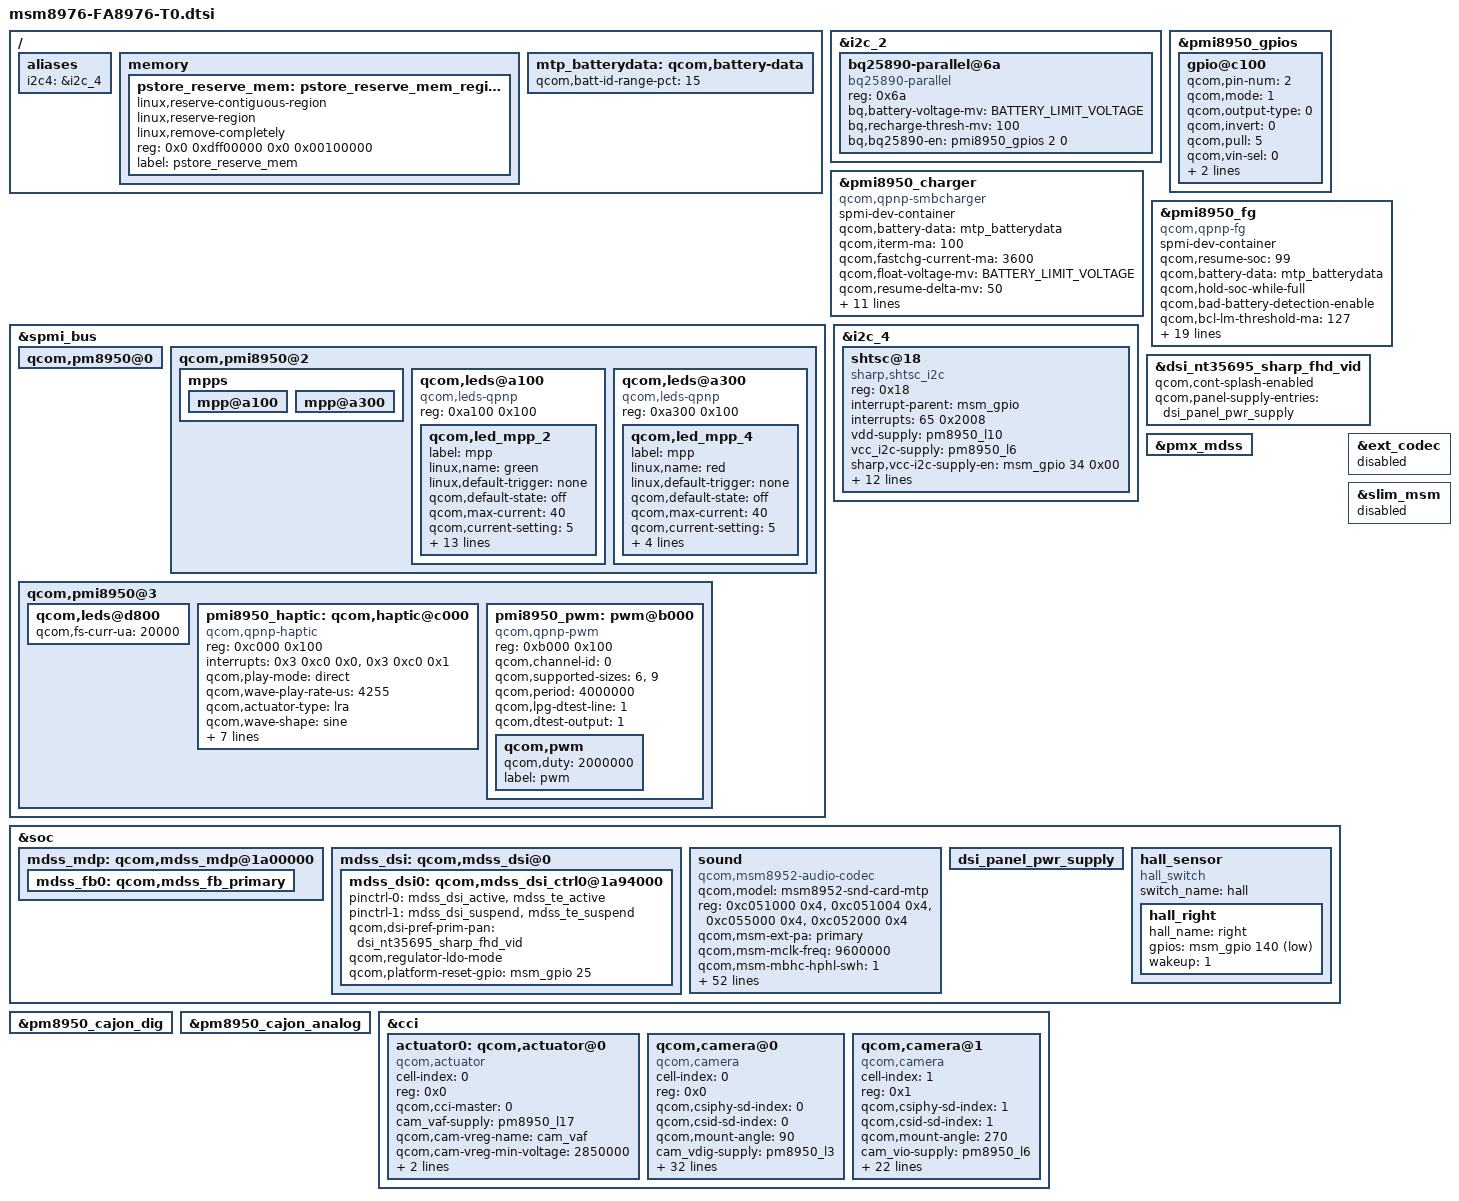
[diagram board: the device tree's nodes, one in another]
/* Copyright (c) 2014, The Linux Foundation. All rights reserved.
 *
 * This program is free software; you can redistribute it and/or modify
 * it under the terms of the GNU General Public License version 2 and
 * only version 2 as published by the Free Software Foundation.
 *
 * This program is distributed in the hope that it will be useful,
 * but WITHOUT ANY WARRANTY; without even the implied warranty of
 * MERCHANTABILITY or FITNESS FOR A PARTICULAR PURPOSE.  See the
 * GNU General Public License for more details.
 */

/* project CPA8_931 */
#define BATTERY_LIMIT_VOLTAGE           (4400)
#define BATTERY_CV_THRESHOLD (BATTERY_LIMIT_VOLTAGE-10)
/ {
       aliases {
                i2c4 = &i2c_4;
        };
	memory {
    		pstore_reserve_mem: pstore_reserve_mem_region@0 {
            	linux,reserve-contiguous-region;
                linux,reserve-region;
                linux,remove-completely;
                reg = <0x0 0xdff00000 0x0 0x00100000>;//3GB DDR, will override at driver code for a right value, so dont take care this value. frankie. 2016-03-15.
                label = "pstore_reserve_mem";
        };
	};
};

/* Begin add bq25890 en configuration */
&i2c_2 { /* BLSP1 QUP2 */
             bq25890-parallel@6a {
                     compatible = "bq25890-parallel";
                     reg = <0x6a>;
                     bq,battery-voltage-mv = <BATTERY_LIMIT_VOLTAGE>;
                     bq,recharge-thresh-mv = <100>;
                     bq,bq25890-en = <&pmi8950_gpios 2 0>;
                  };
};
&pmi8950_gpios {
                gpio@c100 {
                     qcom,pin-num = <2>;
                     qcom,mode = <1>;
                     qcom,output-type = <0>;
                     qcom,invert = <0>;
                     qcom,pull = <5>;
                     qcom,vin-sel = <0>;
                     qcom,src-sel = <2>;
                     qcom,master-en = <1>;
                     status = "okay";
               };
};
/* End add bq25890 en configuration */
/* add pmi zkxiong */
 &pmi8950_charger{
           spmi-dev-container;
           compatible = "qcom,qpnp-smbcharger";
           #address-cells = <1>;
           #size-cells = <1>;
  
	   qcom,battery-data = <&mtp_batterydata>;
           qcom,iterm-ma = <100>;
           qcom,fastchg-current-ma = <3600>;//100mA more
           qcom,float-voltage-mv = <BATTERY_LIMIT_VOLTAGE>;
           qcom,resume-delta-mv = <50>;
   //      /delete-property/ qcom,chg-inhibit-fg;
	   /delete-property/ qcom,chg-led-support;
           /delete-property/ qcom,chg-led-sw-controls;
           qcom,chg-inhibit-fg;
           qcom,dc-psy-type = "Mains";
           qcom,dc-psy-ma = <1500>;
           qcom,rparasitic-uohm = <100000>;
           qcom,bms-psy-name = "bms";
           qcom,thermal-mitigation = <2100 1800 1500 1200 900 600 0>;
           qcom,parallel-usb-min-current-ma = <1500>;
           qcom,parallel-usb-9v-min-current-ma = <1000>;
           qcom,parallel-allowed-lowering-ma = <600>;
           qcom,autoadjust-vfloat;
           /delete-property/ qcom,charge-unknown-battery;
   };

 &pmi8950_fg{
          spmi-dev-container;
          compatible = "qcom,qpnp-fg";
          #address-cells = <1>;
          #size-cells = <1>;
          qcom,resume-soc = <99>;
	  qcom,battery-data = <&mtp_batterydata>;
	  qcom,hold-soc-while-full;
	  qcom,bad-battery-detection-enable;
          status = "okay";
          qcom,bcl-lm-threshold-ma = <127>;
          qcom,bcl-mh-threshold-ma = <405>;
          qcom,fg-cutoff-voltage-mv = <3350>;
          qcom,fg-iterm-ma = <500>;
          qcom,fg-chg-iterm-ma = <100>;
	  qcom,cycle-counter-low-soc = <15>;
 	  qcom,cycle-counter-high-soc = <85>;
          qcom,ext-sense-type;
          qcom,cycle-counter-en;
          qcom,cycle-counter-low-soc = <15>;
          qcom,cycle-counter-high-soc = <85>;
          qcom,capacity-learning-on;
          qcom,fg-cc-cv-threshold-mv = <BATTERY_CV_THRESHOLD>;
          qcom,ext-sense-type;
	  qcom,thermal-coefficients = <0xC2 0x86 0xBB 0x50 0xCF 0x37>;
	  qcom,cold-bat-decidegc = <0>;
          qcom,hot-bat-decidegc = <500>;
          qcom,cool-bat-decidegc = <100>;
          qcom,warm-bat-decidegc = <440>;
          qcom,fg-vbatt-low-threshold = <3600>;
	  qcom,fg-delta-soc = <2>;
  };
/{
mtp_batterydata: qcom,battery-data {
			 qcom,batt-id-range-pct = <15>;
#include "batterydata_CPAT366_100K.dtsi"
#include "batterydata_CPLD373_10K.dtsi"
#include "batterydata_CPTM366_1M.dtsi"
		 };
};
/* end pmi add */

&spmi_bus {
         qcom,pm8950@0 {
                /delete-node/ qcom,leds@a300;
        };
        /*add for led by fengdongjie*/
         qcom,pmi8950@2 {
                mpps{
                      mpp@a100 {status = "okay";};
                      mpp@a300 {status = "okay";};
                };
                /delete-node/ qcom,leds@a100;
                qcom,leds@a100 {
                        compatible = "qcom,leds-qpnp";
                        reg = <0xa100 0x100>;
                        status = "okay";
                        qcom,led_mpp_2 {
                        label = "mpp";
                        linux,name = "green";
                        linux,default-trigger = "none";
                        qcom,default-state = "off";
                        qcom,max-current = <40>;
                        qcom,current-setting = <5>;
                        qcom,use-blink;
                        qcom,id = <6>;
                        qcom,mode = "pwm";
                        qcom,source-sel = <8>;
                        qcom,mode-ctrl = <0x60>;
                        qcom,pwm-channel = <0>;
                        qcom,pwm-us = <2000000>;
                        qcom,start-idx = <1>;
                        qcom,ramp-step-ms = <120>;
                        qcom,duty-pcts = [00 00 00 00 00
                                00 00 00 00 00
                                50 00 00 00 00
                                00 00 00 00 00
                                00];
                        pwms = <&pmi8950_pwm 0 0>;
                        pwm-names="green";
             };
        };
             qcom,leds@a300 {
                  compatible = "qcom,leds-qpnp";
                  reg = <0xa300 0x100>;
                  status = "okay";
                  qcom,led_mpp_4 {
                          label = "mpp";
                          linux,name = "red";
                          linux,default-trigger = "none";
                          qcom,default-state = "off";
                          qcom,max-current = <40>;
                          qcom,current-setting = <5>;
                          qcom,id = <6>;
                          qcom,mode = "manual";
                          qcom,source-sel = <1>;
                          qcom,mode-ctrl = <0x60>;
                  };
           };
   };
         qcom,pmi8950@3 {
                qcom,leds@d800 {
                         qcom,fs-curr-ua = <20000>;
                        /delete-property/ qcom,en-ext-pfet-sc-pro;
                        };
                pmi8950_haptic: qcom,haptic@c000 {
                        compatible = "qcom,qpnp-haptic";
                        reg = <0xc000 0x100>;
                        interrupts = <0x3 0xc0 0x0>,
                                   <0x3 0xc0 0x1>;
                        interrupt-names = "sc-irq", "play-irq";
                        qcom,play-mode = "direct";
                        qcom,wave-play-rate-us = <4255>;
                        qcom,actuator-type = "lra";
                        qcom,wave-shape = "sine";
                        qcom,vmax-mv = <1160>;
                        qcom,ilim-ma = <100>;
                        qcom,sc-deb-cycles = <8>;
                        //qcom,int-pwm-freq-khz = <505>;
                        //qcom,en-brake;
                        qcom,brake-pattern = [03 03 00 00];
                        //qcom,use-play-irq;
                        //qcom,use-sc-irq;
                        qcom,wave-samples = [3e 3e 3e 3e 3e 3e 3e 3e];
                        qcom,wave-rep-cnt = <1>;
                        qcom,wave-samp-rep-cnt = <1>;
                };
                /*add for led by fengdongjie*/
                /delete-node/  pwm@b000;
                pmi8950_pwm: pwm@b000 {
                     compatible = "qcom,qpnp-pwm";
                     reg = <0xb000 0x100>;
                     reg-names = "qpnp-lpg-channel-base";
                     qcom,channel-id = <0>;
                     qcom,supported-sizes = <6>, <9>;
                     qcom,period = <4000000>;
                     qcom,lpg-dtest-line = <1>;
                     qcom,dtest-output = <1>;
                     #pwm-cells = <2>;
                     qcom,pwm {
                             qcom,duty = <2000000>; //PWM duty time in microseconds
                             label = "pwm";
                     };
             };
      };
};

&i2c_4 {
         /* shtsc tw */
	shtsc@18 {
		compatible = "sharp,shtsc_i2c";	
		reg = <0x18>;
		interrupt-parent = <&msm_gpio>;
		interrupts = <65 0x2008>;// high-level trigger. but hard coded in the source.
		vdd-supply = <&pm8950_l10>;
		vcc_i2c-supply = <&pm8950_l6>;
		sharp,vcc-i2c-supply-en = <&msm_gpio 34 0x00>;
		sharp,reset-gpio = <&msm_gpio 64 0x00>;
		sharp,irq-gpio = <&msm_gpio 65 0x2008>;
		pinctrl-names = "pmx_ts_active","pmx_ts_suspend";
		pinctrl-0 = <&ts_int_active &ts_reset_active>;
		pinctrl-1 = <&ts_int_suspend &ts_reset_suspend>;
		sharp,panel-coords = <0 0 1079 1919>; // depends on an LCD resolution (0 0 Xmax-1 Ymax-1)
		sharp,display-coords = <0 0 1079 1919>; // depends on an LCD resolution (0 0 Xmax-1 Ymax-1)
		sharp,i2c-pull-up;
		ts_touch_num_max = <10>;
		ts_pressure_max = <65535>;
		ts_flip_x = <0>;
		ts_flip_y = <0>;
		ts_swap_xy = <0>;

	};
};


/* start william add dtsi for related lcd*/
/* qcom original file: msm8952-mtp.dtsi */
#include "yulong-dsi-panel-nt35695-sharp-fhd-550-video.dtsi"
&dsi_nt35695_sharp_fhd_vid {
        qcom,cont-splash-enabled;
        qcom,panel-supply-entries = <&dsi_panel_pwr_supply>;
};
&pmx_mdss {
	/delete-property/ qcom,num-grp-pins;
	/delete-property/ qcom,pins;
};

&mdss_dsi0 {
	pinctrl-names = "mdss_default", "mdss_sleep";
	pinctrl-0 = <&mdss_dsi_active &mdss_te_active>;
	pinctrl-1 = <&mdss_dsi_suspend &mdss_te_suspend>;
	qcom,dsi-pref-prim-pan = <&dsi_nt35695_sharp_fhd_vid>;
	qcom,regulator-ldo-mode;
	qcom,platform-reset-gpio = <&msm_gpio 25 0>;
	/delete-property/ qcom,platform-enable-gpio;
	/delete-property/ qcom,platform-bklight-en-gpio;
};
/* qcom original file: msm8952-mtp.dtsi */

/* qcom original file: msm8952-mdss.dtsi */
&soc {
mdss_mdp: qcom,mdss_mdp@1a00000 {
mdss_fb0: qcom,mdss_fb_primary {
		  /delete-property/ qcom,mdss-fb-splash-logo-enabled;
	  };
	  };

mdss_dsi: qcom,mdss_dsi@0 {
mdss_dsi0: qcom,mdss_dsi_ctrl0@1a94000 {
		   /delete-property/ vdd-supply; 
	   };
	  };
};
/* qcom original file: msm8952-mdss.dtsi */

/**audio:disable external codec and enable internal codec,by lijiakan--start*/
&ext_codec {
        status = "disabled";
};
&slim_msm{
        status = "disabled";
};

&pm8950_cajon_dig {
        status = "ok";
};

&pm8950_cajon_analog {
        status = "ok";
};
/**audio:disable external codec and enable internal codec,by lijiakan  --end*/
/* fengdongjie add dts for audio start */
&soc {
	/delete-node/ sound-9335;
        sound {
                compatible = "qcom,msm8952-audio-codec";
                qcom,model = "msm8952-snd-card-mtp";
                reg = <0xc051000 0x4>,
                    <0xc051004 0x4>,
                    <0xc055000 0x4>,
                    <0xc052000 0x4>;
                reg-names = "csr_gp_io_mux_mic_ctl",
                        "csr_gp_io_mux_spkr_ctl",
                        "csr_gp_io_lpaif_pri_pcm_pri_mode_muxsel",
                        "csr_gp_io_mux_quin_ctl";

                /delete-property/ qcom,msm-ext-pa;
                qcom,msm-ext-pa = "primary";
                qcom,msm-mclk-freq = <9600000>;
                qcom,msm-mbhc-hphl-swh = <1>;
                qcom,msm-mbhc-gnd-swh = <1>;
                qcom,msm-hs-micbias-type = "external";
                qcom,msm-micbias1-ext-cap;
                /* qcom,msm-spk-boost-ctl = <&msm_gpio 132 0>;*/
                qcom,audio-routing =
                        "RX_BIAS", "MCLK",
                        "SPK_RX_BIAS", "MCLK",
                        "INT_LDO_H", "MCLK",
                        "MIC BIAS External", "Handset Mic",
                        "MIC BIAS External2", "Headset Mic",
                        "MIC BIAS External", "Secondary Mic",
                        "AMIC1", "MIC BIAS External",
                        "AMIC2", "MIC BIAS External2",
                        "AMIC3", "MIC BIAS External";
                qcom,msm-gpios =
                        "pri_i2s";
                        /*"us_eu_gpio";*/
                qcom,pinctrl-names =
                        "all_off",
                        "pri_i2s_act";
                        /*"us_eu_gpio_act",
                          "pri_i2s_us_eu_gpio_act";*/
                pinctrl-names =
                        "all_off",
                        "pri_i2s_act";
                        /*"us_eu_gpio_act",
                          "pri_i2s_us_eu_gpio_act";*/
                /delete-property/ pinctrl-0;
                /delete-property/ pinctrl-1;

                pinctrl-0 = <&cdc_pdm_lines_sus &cdc_pdm_lines_2_sus >;
                pinctrl-1 = <&cdc_pdm_lines_act &cdc_pdm_lines_2_act >;

                /delete-property/ qcom,cdc-us-euro-gpios;
                asoc-platform = <&pcm0>, <&pcm1>, <&pcm2>, <&voip>, <&voice>,
                        <&loopback>, <&compress>, <&hostless>,
                        <&afe>, <&lsm>, <&routing>, <&lpa>,
                        <&voice_svc>;
                asoc-platform-names = "msm-pcm-dsp.0", "msm-pcm-dsp.1", "msm-pcm-dsp.2",
                        "msm-voip-dsp", "msm-pcm-voice", "msm-pcm-loopback",
                        "msm-compress-dsp", "msm-pcm-hostless", "msm-pcm-afe",
                        "msm-lsm-client", "msm-pcm-routing", "msm-pcm-lpa",
                        "msm-voice-svc";
                asoc-cpu = <&dai_pri_auxpcm>, <&dai_hdmi>,
                        <&dai_mi2s0>, <&dai_mi2s1>, <&dai_mi2s2>, <&dai_mi2s3>,
                        <&dai_mi2s5>,<&dai_mi2s6>,
                        <&sb_0_rx>, <&sb_0_tx>, <&sb_1_rx>, <&sb_1_tx>,
                        <&sb_3_rx>, <&sb_3_tx>, <&sb_4_rx>, <&sb_4_tx>,
                        <&bt_sco_rx>, <&bt_sco_tx>, <&int_fm_rx>, <&int_fm_tx>,
                        <&afe_pcm_rx>, <&afe_pcm_tx>, <&afe_proxy_rx>, <&afe_proxy_tx>,
                        <&incall_record_rx>, <&incall_record_tx>, <&incall_music_rx>,
                        <&incall_music_2_rx>;
                asoc-cpu-names = "msm-dai-q6-auxpcm.1", "msm-dai-q6-hdmi.8",
                        "msm-dai-q6-mi2s.0", "msm-dai-q6-mi2s.1",
                        "msm-dai-q6-mi2s.2", "msm-dai-q6-mi2s.3",
                        "msm-dai-q6-mi2s.5","msm-dai-q6-mi2s.6",
                        "msm-dai-q6-dev.16384", "msm-dai-q6-dev.16385",
                        "msm-dai-q6-dev.16386", "msm-dai-q6-dev.16387",
                        "msm-dai-q6-dev.16390", "msm-dai-q6-dev.16391",
                        "msm-dai-q6-dev.16392", "msm-dai-q6-dev.16393",
                        "msm-dai-q6-dev.12288", "msm-dai-q6-dev.12289",
                        "msm-dai-q6-dev.12292", "msm-dai-q6-dev.12293",
                        "msm-dai-q6-dev.224", "msm-dai-q6-dev.225",
                        "msm-dai-q6-dev.241", "msm-dai-q6-dev.240",
                        "msm-dai-q6-dev.32771", "msm-dai-q6-dev.32772",
                        "msm-dai-q6-dev.32773", "msm-dai-q6-dev.32770";
                asoc-codec = <&stub_codec>, <&pm8950_cajon_dig>;
                asoc-codec-names = "msm-stub-codec.1", "cajon_codec";
                /delete-property/ asoc-wsa-codec-names;
                /delete-property/ asoc-wsa-codec-prefixes;
                /delete-property/ msm-vdd-wsa-switch-supply;
                /delete-property/ qcom,msm-vdd-wsa-switch-voltage;
                /delete-property/ qcom,msm-vdd-wsa-switch-current;
        };

};
/* fengdongjie add dts for audio end */

/* qcom original file: msm8952-mdss-panels.dtsi */
&soc {
dsi_panel_pwr_supply: dsi_panel_pwr_supply {
			      /delete-node/ qcom,panel-supply-entry@0;
		      };
};
/* qcom original file: msm8952-mdss-panels.dtsi */

/* end william add dtsi for related lcd*/


/* Begin add camera dts file for 8952 platform */

&cci {

	/delete-node/ qcom,actuator@0;
	/delete-node/ qcom,actuator@1;
	/delete-node/ qcom,camera@0;
	/delete-node/ qcom,camera@1;
	/delete-node/ qcom,camera@2;
	/delete-node/ qcom,camera@78;
	/delete-node/ qcom,eeprom@0;
	/delete-node/ qcom,eeprom@1;
	/delete-node/ qcom,eeprom@2;


	actuator0: qcom,actuator@0 {
		cell-index = <0>;
		reg = <0x0>;
		compatible = "qcom,actuator";
		qcom,cci-master = <0>;
		cam_vaf-supply = <&pm8950_l17>; //cn:
		qcom,cam-vreg-name = "cam_vaf";
		qcom,cam-vreg-min-voltage = <2850000>;
		qcom,cam-vreg-max-voltage = <2850000>;
		qcom,cam-vreg-op-mode = <100000>;
	};


/*	eeprom0: qcom,eeprom@0 {
		cell-index = <0>;
		reg = <0x0>;
		qcom,eeprom-name = "samsung_s5k3m2";
		compatible = "qcom,eeprom";
		qcom,slave-addr = <0xa0>;
		qcom,i2c-freq-mode = <1>;
		qcom,cci-master = <0>;
		qcom,num-blocks = <1>;

		qcom,page0 = <0 0 0 0 0 0>;
		qcom,poll0 = <0 0 0 0 0 0>;
		qcom,saddr0 = <0xa0>;
		qcom,mem0 = <0x17F6 0x0000 2 0 1 0>;

		cam_vdig-supply = <&pm8950_l23>;	//DVDD	1.2 must change to 1.05V !!!
		cam_vio-supply = <&pm8950_l6>;		//DOVDD	1.8
		cam_vana-supply = <&pm8950_l6>;		//for place ,actually use GPIO
		cam_vaf-supply = <&pm8950_l17>;		//VAAM	2.85
		qcom,cam-vreg-name = "cam_vdig", "cam_vio", "cam_vana", "cam_vaf";
		qcom,cam-vreg-min-voltage = <1050000 1800000 1800000 2850000>;
		qcom,cam-vreg-max-voltage = <1050000 1800000 1800000 2850000>;
		qcom,cam-vreg-op-mode = <200000 100000 100000 100000>;
		pinctrl-names = "cam_default", "cam_suspend";
		pinctrl-0 = <&cam_sensor_mclk0_default
				&cam_sensor_rear_default>;
		pinctrl-1 = <&cam_sensor_mclk0_sleep &cam_sensor_rear_sleep>;
		qcom,gpio-no-mux = <0>;
		gpios = <&msm_gpio 26 0>,	//CAM_MCLK0
			<&msm_gpio 129 0>,		//CAM0_RST
			<&msm_gpio 69 0>,		//MCAM_AVDD_EN
			<&msm_gpio 32 0>;		//MCAM_DOVDD_EN

		qcom,gpio-reset = <1>;
		qcom,gpio-vana = <2>;
		qcom,gpio-vio = <3>;
		qcom,gpio-req-tbl-num = <0 1 2 3>;
		qcom,gpio-req-tbl-flags = <1 0 0 0>;

		qcom,gpio-req-tbl-label = "CAMIF_MCLK0",
			"CAM_RESET0",
			"CAM_VANA0",
			"CAM_VIO0";


                qcom,cam-power-seq-type = "sensor_gpio",
                    "sensor_gpio",

                    "sensor_vreg",
		    "sensor_vreg",
                    "sensor_gpio",
                    "sensor_clk",
                    "sensor_gpio",
                    "sensor_i2c_mux";
                qcom,cam-power-seq-val = "sensor_gpio_reset",
                    "sensor_gpio_vana",
                    "cam_vaf",
		    "cam_vdig",
		    "cam_vio",
                    "sensor_cam_mclk",
		    "sensor_gpio_reset",
                    "none";
                qcom,cam-power-seq-cfg-val = <0 1 1 1 1 24000000 1 0>;
                qcom,cam-power-seq-delay = <5 5 5 5 5 5 5 5>;
		clocks = <&clock_gcc clk_mclk0_clk_src>,
			     <&clock_gcc clk_gcc_camss_mclk0_clk>;
		clock-names = "cam_src_clk", "cam_clk";
	};
*/

	qcom,camera@0 {
		cell-index = <0>;
		compatible = "qcom,camera";
		reg = <0x0>;
		qcom,csiphy-sd-index = <0>;
		qcom,csid-sd-index = <0>;
		qcom,mount-angle = <90>;
	//	qcom,eeprom-src = <&eeprom0>;
	//	qcom,actuator-src = <&actuator0>;
//		qcom,led-flash-src = <&led_flash0>;
		cam_vdig-supply = <&pm8950_l3>;	//DVDD	1.2 must change to 1.05V !!!
		cam_vio-supply = <&pm8950_l6>;		//no use DOVDD	1.8
		cam_vana-supply = <&pm8950_l6>;		//for place ,actually use GPIO
		cam_vaf-supply = <&pm8950_l17>;		//VAAM	2.85
		qcom,cam-vreg-name = "cam_vdig", "cam_vio", "cam_vana", "cam_vaf";
		qcom,cam-vreg-min-voltage = <1050000 1800000 1800000 2850000>;
		qcom,cam-vreg-max-voltage = <1050000 1800000 1800000 2850000>;
		qcom,cam-vreg-op-mode = <200000 100000 100000 100000>;
		pinctrl-names = "cam_default", "cam_suspend";
		pinctrl-0 = <&cam_sensor_mclk0_default
				&cam_sensor_rear_default>;
		pinctrl-1 = <&cam_sensor_mclk0_sleep &cam_sensor_rear_sleep>;
		qcom,gpio-no-mux = <0>;
		gpios = <&msm_gpio 26 0>,	//CAM_MCLK0
			<&msm_gpio 129 0>,		//CAM0_RST
			<&msm_gpio 69 0>,		//MCAM_AVDD_EN
			<&msm_gpio 32 0>;		//MCAM_DOVDD_EN

		qcom,gpio-reset = <1>;
		qcom,gpio-vana = <2>;
		qcom,gpio-vio = <3>;
		qcom,gpio-req-tbl-num = <0 1 2 3>;
		qcom,gpio-req-tbl-flags = <1 0 0 0>;

		qcom,gpio-req-tbl-label = "CAMIF_MCLK0",
			"CAM_RESET0",
			"CAM_VANA0",
			"CAM_VIO0";

		qcom,csi-lane-assign = <0x4320>;
		qcom,csi-lane-mask = <0x1f>;
		qcom,sensor-position = <0>;
		qcom,sensor-mode = <0>;
		qcom,cci-master = <1>;
		status = "ok";
		clocks = <&clock_gcc clk_mclk0_clk_src>,
			     <&clock_gcc clk_gcc_camss_mclk0_clk>;
		clock-names = "cam_src_clk", "cam_clk";
	};

	//OV5648
	qcom,camera@1 {
		cell-index = <1>;
		compatible = "qcom,camera";
		reg = <0x1>;
		qcom,csiphy-sd-index = <1>;
		qcom,csid-sd-index = <1>;
		qcom,mount-angle = <270>;

		cam_vio-supply = <&pm8950_l6>;		//no use DOVDD	1.8
		cam_vana-supply = <&pm8950_l22>;	//AVDD 2.85

		qcom,cam-vreg-name = "cam_vio", "cam_vana";
		qcom,cam-vreg-min-voltage = <1800000 2800000>;
		qcom,cam-vreg-max-voltage = <1800000 2800000>;
		qcom,cam-vreg-op-mode = <105000 80000>;
		qcom,gpio-no-mux = <0>;
		pinctrl-names = "cam_default", "cam_suspend";
		pinctrl-0 = <&cam_sensor_mclk2_default &cam_sensor_front1_default>;
		pinctrl-1 = <&cam_sensor_mclk2_sleep &cam_sensor_front1_sleep>;
		gpios = <&msm_gpio 28 0>,//MCLK1
            <&msm_gpio 131 0>, //RESET
			<&msm_gpio 33 0>; //dovdd

		qcom,gpio-reset = <1>;
		qcom,gpio-vio = <2>;
		qcom,gpio-req-tbl-num = <0 1 2>;
		qcom,gpio-req-tbl-flags = <1 0 0>;
		qcom,gpio-req-tbl-label = "CAMIF_MCLK2",
					  "CAM_RESET2",
					  "CAM_VIO2";
		qcom,sensor-position = <1>;
		qcom,sensor-mode = <0>;
		qcom,cci-master = <0>;
		status = "ok";
		clocks = <&clock_gcc clk_mclk2_clk_src>,
			<&clock_gcc clk_gcc_camss_mclk2_clk>;
		clock-names = "cam_src_clk", "cam_clk";
	};

};
/* Added by chenshuanglong for hall sensor 2016/03/2 */
&soc {
    hall_sensor {
        compatible = "hall_switch";
        switch_name = "hall";
        hall_right {
            hall_name = "right";
            gpios = <&msm_gpio 140 0x1>;
            wakeup = <1>;
        };
    };
};
/* end added by chenshuanglong for hall sensor 2016/03/2 */
